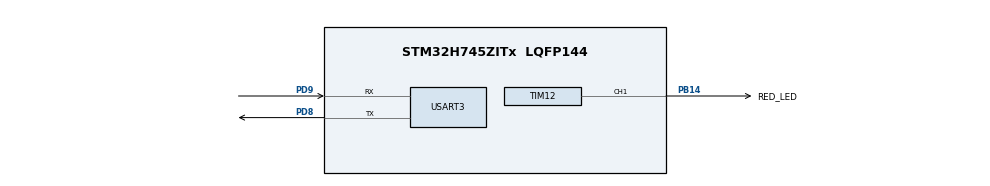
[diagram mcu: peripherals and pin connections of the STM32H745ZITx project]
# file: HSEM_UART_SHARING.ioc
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CORTEX_M7.CPU_DCache=Enabled
CORTEX_M7.CPU_ICache=Enabled
CortexM4.IPs=FATFS_M4\:I,FREERTOS_M4\:I,IWDG2\:I,RCC,WWDG2\:I,DMA,BDMA,MDMA,NVIC2\:I,USART3,ETH,DEBUG,PDM2PCM_M4\:I,PWR,RESMGR_UTILITY,SYS_M4\:I,USB_DEVICE_M4\:I,USB_HOST_M4\:I,CORTEX_M4\:I,OPENAMP_M4\:I,VREFBUF,TIM12
CortexM7.IPs=FATFS_M7\:I,FREERTOS_M7\:I,IWDG1\:I,RCC\:I,WWDG1\:I,DMA\:I,BDMA\:I,MDMA\:I,NVIC1\:I,SYS\:I,USART3\:I,USB_OTG_FS\:I,ETH\:I,CORTEX_M7\:I,DEBUG\:I,PDM2PCM_M7\:I,PWR\:I,RESMGR_UTILITY\:I,USB_DEVICE_M7\:I,USB_HOST_M7\:I,OPENAMP_M7\:I,VREFBUF\:I,TIM12\:I
Mcu.Family=STM32H7
Mcu.Name=STM32H745ZITx
Mcu.Package=LQFP144
NVIC1.HSEM1_IRQn=true\:0\:0\:false\:false\:true\:true\:true\:true
NVIC1.PriorityGroup=NVIC_PRIORITYGROUP_4
NVIC2.HSEM2_IRQn=true\:0\:0\:false\:false\:true\:true\:true\:true
NVIC2.PriorityGroup=NVIC_PRIORITYGROUP_4
PB14.GPIO_Label=RED_LED
PB14.GPIO_Speed=GPIO_SPEED_FREQ_VERY_HIGH
PB14.PinAttribute=CortexM7
PB14.Signal=S_TIM12_CH1
PD8.Mode=Asynchronous
PD8.PinAttribute=CortexM7
PD8.Signal=USART3_TX
PD9.Mode=Asynchronous
PD9.PinAttribute=CortexM7
PD9.Signal=USART3_RX
ProjectManager.HeapSize=M4-0x200,M7-0x200
ProjectManager.StackSize=M4-0x400,M7-0x400
ProjectManager.TargetToolchain=STM32CubeIDE
RCC.ADCFreq_Value=129000000
RCC.APB1Freq_Value=50000000
RCC.APB2Freq_Value=100000000
RCC.APB3Freq_Value=100000000
RCC.APB4Freq_Value=100000000
RCC.CortexFreq_Value=100000000
RCC.D2PPRE1=RCC_APB1_DIV2
RCC.DIVM1=4
RCC.DIVM3=22
RCC.DIVN1=12
RCC.DIVN3=169
RCC.DIVQ3=4
RCC.HCLKFreq_Value=100000000
RCC.PLL1_VCI_Range-AdvancedSettings=RCC_PLL1VCIRANGE_0
RCC.PLL2FRACN=0
RCC.PLL2_VCI_Range-AdvancedSettings=RCC_PLL2VCIRANGE_0
RCC.PLL2_VCO_SEL-AdvancedSettings=RCC_PLL2VCOMEDIUM
RCC.PLL3FRACN=0
RCC.PLLFRACN=4096
RCC.SYSCLKFreq_VALUE=100000000
RCC.SYSCLKSource=RCC_SYSCLKSOURCE_PLLCLK
RCC.SupplySource=PWR_DIRECT_SMPS_SUPPLY
RCC.USBCLockSelection=RCC_USBCLKSOURCE_PLL3
RCC.USBFreq_Value=122909090.9090909
SH.S_TIM12_CH1.0=TIM12_CH1,PWM Generation1 CH1
TIM12.Channel-PWM\ Generation1\ CH1=TIM_CHANNEL_1
TIM12.Period=100
TIM12.Prescaler=10000
USART3.VirtualMode-Asynchronous=VM_ASYNC
VP_SYS_M4_VS_Systick.Mode=SysTick
VP_TIM12_VS_ClockSourceINT.Mode=Internal
board=NUCLEO-H745ZI-Q

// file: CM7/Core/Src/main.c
/* USER CODE BEGIN Header */
/**
  ******************************************************************************
  * @file           : main.c
  * @brief          : Main program body
  ******************************************************************************
  * @attention
  *
  * <h2><center>&copy; Copyright (c) 2022 STMicroelectronics.
  * All rights reserved.</center></h2>
  *
  * This software component is licensed by ST under BSD 3-Clause license,
  * the "License"; You may not use this file except in compliance with the
  * License. You may obtain a copy of the License at:
  *                        opensource.org/licenses/BSD-3-Clause
  *
  ******************************************************************************
  */
/* USER CODE END Header */
#include "main.h"

/* USER CODE BEGIN Includes */
#include <stdio.h>
#include <string.h>
/* USER CODE END Includes */

/* USER CODE BEGIN PD */

#ifndef HSEM_ID_0
#define HSEM_ID_0 (0U) /* HW semaphore 0*/
#endif

#define HSEM_PROCESS_ID 4
/* USER CODE END PD */

TIM_HandleTypeDef htim12;

UART_HandleTypeDef huart3;

/* USER CODE BEGIN PV */
uint8_t semaphore_status = 0, PWM_Duty = 0;
char UART_String[25];
/* USER CODE END PV */

void SystemClock_Config(void);
static void MX_GPIO_Init(void);
static void MX_USART3_UART_Init(void);
static void MX_TIM12_Init(void);

int main(void)
{
/* USER CODE BEGIN Boot_Mode_Sequence_0 */
  int32_t timeout;
/* USER CODE END Boot_Mode_Sequence_0 */

  /* Enable I-Cache---------------------------------------------------------*/
  SCB_EnableICache();

  /* Enable D-Cache---------------------------------------------------------*/
  SCB_EnableDCache();

/* USER CODE BEGIN Boot_Mode_Sequence_1 */
  /* Wait until CPU2 boots and enters in stop mode or timeout*/
  timeout = 0xFFFF;
  while((__HAL_RCC_GET_FLAG(RCC_FLAG_D2CKRDY) != RESET) && (timeout-- > 0));
  if ( timeout < 0 )
  {
  Error_Handler();
  }
/* USER CODE END Boot_Mode_Sequence_1 */
  /* MCU Configuration--------------------------------------------------------*/

  /* Reset of all peripherals, Initializes the Flash interface and the Systick. */
  HAL_Init();

  /* Configure the system clock */
  SystemClock_Config();
/* USER CODE BEGIN Boot_Mode_Sequence_2 */
/* When system initialization is finished, Cortex-M7 will release Cortex-M4 by means of
HSEM notification */
/*HW semaphore Clock enable*/
__HAL_RCC_HSEM_CLK_ENABLE();
/*Take HSEM */
HAL_HSEM_FastTake(HSEM_ID_0);
/*Release HSEM in order to notify the CPU2(CM4)*/
HAL_HSEM_Release(HSEM_ID_0,0);
/* wait until CPU2 wakes up from stop mode */
timeout = 0xFFFF;
while((__HAL_RCC_GET_FLAG(RCC_FLAG_D2CKRDY) == RESET) && (timeout-- > 0));
if ( timeout < 0 )
{
Error_Handler();
}
/* USER CODE END Boot_Mode_Sequence_2 */

  /* Initialize all configured peripherals */
  MX_GPIO_Init();
  MX_USART3_UART_Init();
  MX_TIM12_Init();
  /* USER CODE BEGIN 2 */
  HAL_HSEM_ActivateNotification(__HAL_HSEM_SEMID_TO_MASK(HSEM_ID_0));
  /* USER CODE END 2 */

  /* Infinite loop */
  /* USER CODE BEGIN WHILE */
  while (1)
  {
	  if(HAL_HSEM_Take(HSEM_ID_0, HSEM_PROCESS_ID) == HAL_OK)
	  {
		  semaphore_status = 0;
		  HAL_NVIC_DisableIRQ(HSEM1_IRQn);
		  snprintf(UART_String,sizeof(UART_String),"CM7 -> PWM Output %d%%\r\n",PWM_Duty);
		  HAL_UART_Transmit(&huart3, UART_String, 23, 100);
		  TIM12->CCR1 = PWM_Duty;
		  HAL_TIM_PWM_Start(&htim12, TIM_CHANNEL_1);
		  (PWM_Duty < 100) ? (PWM_Duty++) : (PWM_Duty = 0);
		  HAL_HSEM_Release(HSEM_ID_0, HSEM_PROCESS_ID);
	  }
	  else
	  {
		  (semaphore_status == 1) ? HAL_NVIC_EnableIRQ(HSEM1_IRQn) : 0;
		  //while(semaphore_status == 0);	//wait till HSEM interrupt will occur
	  }

	  HAL_Delay(1000);
    /* USER CODE END WHILE */

  }
}

void SystemClock_Config(void)
{
  RCC_OscInitTypeDef RCC_OscInitStruct = {0};
  RCC_ClkInitTypeDef RCC_ClkInitStruct = {0};

  /** Supply configuration update enable
  */
  HAL_PWREx_ConfigSupply(PWR_DIRECT_SMPS_SUPPLY);
  /** Configure the main internal regulator output voltage
  */
  __HAL_PWR_VOLTAGESCALING_CONFIG(PWR_REGULATOR_VOLTAGE_SCALE3);

  while(!__HAL_PWR_GET_FLAG(PWR_FLAG_VOSRDY)) {}
  /** Initializes the RCC Oscillators according to the specified parameters
  * in the RCC_OscInitTypeDef structure.
  */
  RCC_OscInitStruct.OscillatorType = RCC_OSCILLATORTYPE_HSI;
  RCC_OscInitStruct.HSIState = RCC_HSI_DIV1;
  RCC_OscInitStruct.HSICalibrationValue = RCC_HSICALIBRATION_DEFAULT;
  RCC_OscInitStruct.PLL.PLLState = RCC_PLL_ON;
  RCC_OscInitStruct.PLL.PLLSource = RCC_PLLSOURCE_HSI;
  RCC_OscInitStruct.PLL.PLLM = 4;
  RCC_OscInitStruct.PLL.PLLN = 12;
  RCC_OscInitStruct.PLL.PLLP = 2;
  RCC_OscInitStruct.PLL.PLLQ = 2;
  RCC_OscInitStruct.PLL.PLLR = 2;
  RCC_OscInitStruct.PLL.PLLRGE = RCC_PLL1VCIRANGE_3;
  RCC_OscInitStruct.PLL.PLLVCOSEL = RCC_PLL1VCOWIDE;
  RCC_OscInitStruct.PLL.PLLFRACN = 4096;
  if (HAL_RCC_OscConfig(&RCC_OscInitStruct) != HAL_OK)
  {
    Error_Handler();
  }
  /** Initializes the CPU, AHB and APB buses clocks
  */
  RCC_ClkInitStruct.ClockType = RCC_CLOCKTYPE_HCLK|RCC_CLOCKTYPE_SYSCLK
                              |RCC_CLOCKTYPE_PCLK1|RCC_CLOCKTYPE_PCLK2
                              |RCC_CLOCKTYPE_D3PCLK1|RCC_CLOCKTYPE_D1PCLK1;
  RCC_ClkInitStruct.SYSCLKSource = RCC_SYSCLKSOURCE_PLLCLK;
  RCC_ClkInitStruct.SYSCLKDivider = RCC_SYSCLK_DIV1;
  RCC_ClkInitStruct.AHBCLKDivider = RCC_HCLK_DIV1;
  RCC_ClkInitStruct.APB3CLKDivider = RCC_APB3_DIV1;
  RCC_ClkInitStruct.APB1CLKDivider = RCC_APB1_DIV2;
  RCC_ClkInitStruct.APB2CLKDivider = RCC_APB2_DIV1;
  RCC_ClkInitStruct.APB4CLKDivider = RCC_APB4_DIV1;

  if (HAL_RCC_ClockConfig(&RCC_ClkInitStruct, FLASH_LATENCY_2) != HAL_OK)
  {
    Error_Handler();
  }
}

static void MX_TIM12_Init(void)
{

  TIM_ClockConfigTypeDef sClockSourceConfig = {0};
  TIM_OC_InitTypeDef sConfigOC = {0};

  htim12.Instance = TIM12;
  htim12.Init.Prescaler = 10000;
  htim12.Init.CounterMode = TIM_COUNTERMODE_UP;
  htim12.Init.Period = 100;
  htim12.Init.ClockDivision = TIM_CLOCKDIVISION_DIV1;
  htim12.Init.AutoReloadPreload = TIM_AUTORELOAD_PRELOAD_DISABLE;
  if (HAL_TIM_Base_Init(&htim12) != HAL_OK)
  {
    Error_Handler();
  }
  sClockSourceConfig.ClockSource = TIM_CLOCKSOURCE_INTERNAL;
  if (HAL_TIM_ConfigClockSource(&htim12, &sClockSourceConfig) != HAL_OK)
  {
    Error_Handler();
  }
  if (HAL_TIM_PWM_Init(&htim12) != HAL_OK)
  {
    Error_Handler();
  }
  sConfigOC.OCMode = TIM_OCMODE_PWM1;
  sConfigOC.Pulse = 0;
  sConfigOC.OCPolarity = TIM_OCPOLARITY_HIGH;
  sConfigOC.OCFastMode = TIM_OCFAST_DISABLE;
  if (HAL_TIM_PWM_ConfigChannel(&htim12, &sConfigOC, TIM_CHANNEL_1) != HAL_OK)
  {
    Error_Handler();
  }
  HAL_TIM_MspPostInit(&htim12);

}

static void MX_USART3_UART_Init(void)
{

  huart3.Instance = USART3;
  huart3.Init.BaudRate = 115200;
  huart3.Init.WordLength = UART_WORDLENGTH_8B;
  huart3.Init.StopBits = UART_STOPBITS_1;
  huart3.Init.Parity = UART_PARITY_NONE;
  huart3.Init.Mode = UART_MODE_TX_RX;
  huart3.Init.HwFlowCtl = UART_HWCONTROL_NONE;
  huart3.Init.OverSampling = UART_OVERSAMPLING_16;
  huart3.Init.OneBitSampling = UART_ONE_BIT_SAMPLE_DISABLE;
  huart3.Init.ClockPrescaler = UART_PRESCALER_DIV1;
  huart3.AdvancedInit.AdvFeatureInit = UART_ADVFEATURE_NO_INIT;
  if (HAL_UART_Init(&huart3) != HAL_OK)
  {
    Error_Handler();
  }
  if (HAL_UARTEx_SetTxFifoThreshold(&huart3, UART_TXFIFO_THRESHOLD_1_8) != HAL_OK)
  {
    Error_Handler();
  }
  if (HAL_UARTEx_SetRxFifoThreshold(&huart3, UART_RXFIFO_THRESHOLD_1_8) != HAL_OK)
  {
    Error_Handler();
  }
  if (HAL_UARTEx_DisableFifoMode(&huart3) != HAL_OK)
  {
    Error_Handler();
  }

}

static void MX_GPIO_Init(void)
{

  /* GPIO Ports Clock Enable */
  __HAL_RCC_GPIOB_CLK_ENABLE();
  __HAL_RCC_GPIOD_CLK_ENABLE();

}

/* USER CODE BEGIN 4 */
void HAL_HSEM_FreeCallback(uint32_t SemMask)
{
	if((SemMask & __HAL_HSEM_SEMID_TO_MASK(HSEM_ID_0)) != 0)
	{
		semaphore_status = 1;
	}
}
/* USER CODE END 4 */

void Error_Handler(void)
{
  __disable_irq();
  while (1)
  {
  }
}

/************************ (C) COPYRIGHT STMicroelectronics *****END OF FILE****/
